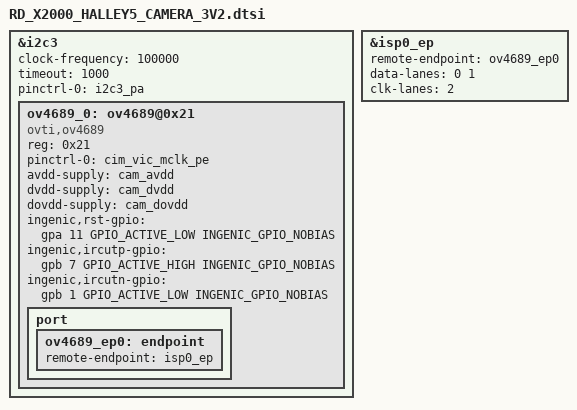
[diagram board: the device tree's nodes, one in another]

&i2c3 {
	status = "okay";
	clock-frequency = <100000>;
	timeout = <1000>;
	pinctrl-names = "default";
	pinctrl-0 = <&i2c3_pa>;

	/*RD_X2000_HALLEY5_CAMERA_V3.2*/
	ov4689_0:ov4689@0x21 {
		status = "ok";
		compatible = "ovti,ov4689";
		reg = <0x21>;
		pinctrl-names = "default";
		pinctrl-0 = <&cim_vic_mclk_pe>;

		avdd-supply = <&cam_avdd>;
		dvdd-supply = <&cam_dvdd>;
		dovdd-supply = <&cam_dovdd>;
		ingenic,rst-gpio = <&gpa 11 GPIO_ACTIVE_LOW INGENIC_GPIO_NOBIAS>;
		ingenic,ircutp-gpio = <&gpb 7 GPIO_ACTIVE_HIGH INGENIC_GPIO_NOBIAS>;
		ingenic,ircutn-gpio = <&gpb 1 GPIO_ACTIVE_LOW INGENIC_GPIO_NOBIAS>;

		port {
			ov4689_ep0:endpoint {
				remote-endpoint = <&isp0_ep>;
			};
		};
	};
};

&isp0_ep {
	remote-endpoint = <&ov4689_ep0>;
	data-lanes = <0 1>;
	clk-lanes = <2>;
};


